VERSION ""

NS_ :

BS_:

BU_: USCU LSU LCU VCU ACU
VAL_TABLE_ Agv_St 2 "ON" 1 "STOP" 0 "Inivd" ;

BO_ 3221225472 VECTOR__INDEPENDENT_SIG_MSG: 0 Vector__XXX
 SG_ VCU1_RemoteValid : 0|1@1+ (1,0) [0|1] "" Vector__XXX

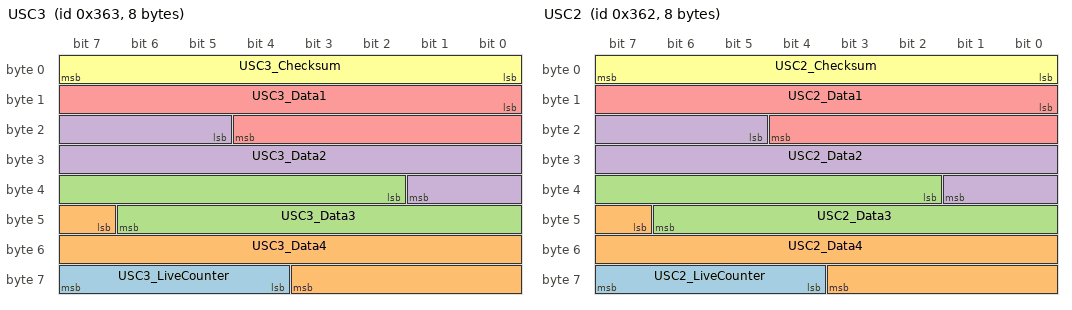
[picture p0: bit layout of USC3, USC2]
BO_ 867 USC3: 8 USCU
 SG_ USC3_LiveCounter : 60|4@1+ (1,0) [0|15] "" Vector__XXX
 SG_ USC3_Data4 : 47|13@1+ (1,0) [0|5000] "mm" Vector__XXX
 SG_ USC3_Data3 : 34|13@1+ (1,0) [0|5000] "mm" Vector__XXX
 SG_ USC3_Data2 : 21|13@1+ (1,0) [0|5000] "mm" Vector__XXX
 SG_ USC3_Data1 : 8|13@1+ (1,0) [0|5000] "mm" Vector__XXX
 SG_ USC3_Checksum : 0|8@1+ (1,0) [0|255] "" Vector__XXX

BO_ 866 USC2: 8 USCU
 SG_ USC2_LiveCounter : 60|4@1+ (1,0) [0|15] "" Vector__XXX
 SG_ USC2_Data4 : 47|13@1+ (1,0) [0|5000] "" Vector__XXX
 SG_ USC2_Data3 : 34|13@1+ (1,0) [0|5000] "mm" Vector__XXX
 SG_ USC2_Data2 : 21|13@1+ (1,0) [0|5000] "mm" Vector__XXX
 SG_ USC2_Data1 : 8|13@1+ (1,0) [0|5000] "mm" Vector__XXX
 SG_ USC2_Checksum : 0|8@1+ (1,0) [0|255] "" Vector__XXX

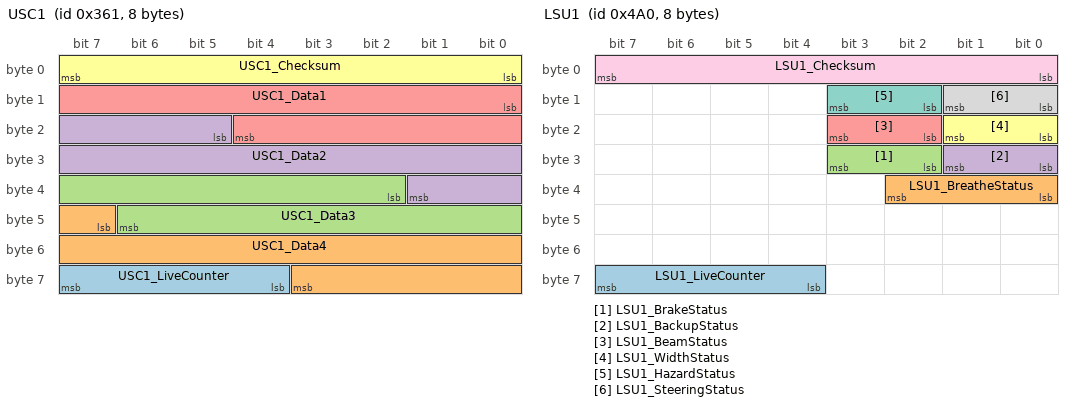
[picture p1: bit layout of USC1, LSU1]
BO_ 865 USC1: 8 USCU
 SG_ USC1_LiveCounter : 60|4@1+ (1,0) [0|15] "" Vector__XXX
 SG_ USC1_Data4 : 47|13@1+ (1,0) [0|5000] "mm" Vector__XXX
 SG_ USC1_Data3 : 34|13@1+ (1,0) [0|5000] "mm" Vector__XXX
 SG_ USC1_Data2 : 21|13@1+ (1,0) [0|5000] "mm" Vector__XXX
 SG_ USC1_Data1 : 8|13@1+ (1,0) [0|5000] "mm" Vector__XXX
 SG_ USC1_Checksum : 0|8@1+ (1,0) [0|255] "" Vector__XXX

BO_ 1184 LSU1: 8 LSU
 SG_ LSU1_LiveCounter : 60|4@1+ (1,0) [0|15] "count" Vector__XXX
 SG_ LSU1_BreatheStatus : 32|3@1+ (1,0) [0|1] "" Vector__XXX
 SG_ LSU1_BrakeStatus : 26|2@1+ (1,0) [0|3] "" Vector__XXX
 SG_ LSU1_BackupStatus : 24|2@1+ (1,0) [0|3] "" Vector__XXX
 SG_ LSU1_BeamStatus : 18|2@1+ (1,0) [0|1] "" Vector__XXX
 SG_ LSU1_WidthStatus : 16|2@1+ (1,0) [0|3] "" Vector__XXX
 SG_ LSU1_HazardStatus : 10|2@1+ (1,0) [0|3] "" Vector__XXX
 SG_ LSU1_SteeringStatus : 8|2@1+ (1,0) [0|1] "" Vector__XXX
 SG_ LSU1_Checksum : 0|8@1+ (1,0) [0|255] "check" Vector__XXX

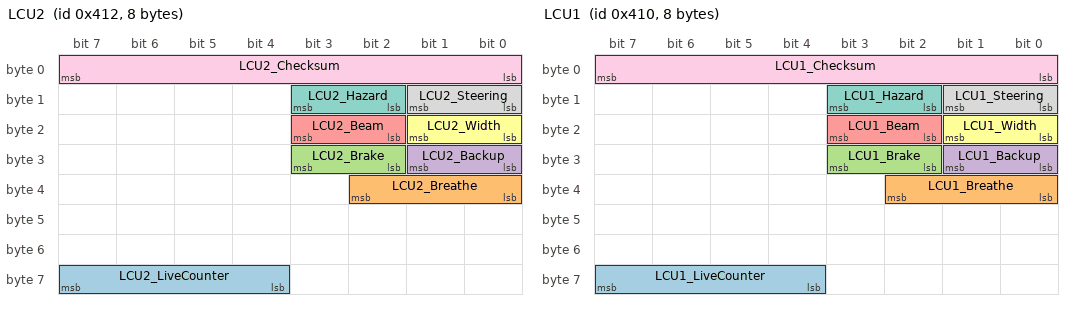
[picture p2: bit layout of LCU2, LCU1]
BO_ 1042 LCU2: 8 LCU
 SG_ LCU2_LiveCounter : 60|4@1+ (1,0) [0|15] "count" Vector__XXX
 SG_ LCU2_Breathe : 32|3@1+ (1,0) [0|3] "" Vector__XXX
 SG_ LCU2_Brake : 26|2@1+ (1,0) [0|3] "" Vector__XXX
 SG_ LCU2_Backup : 24|2@1+ (1,0) [0|3] "" Vector__XXX
 SG_ LCU2_Beam : 18|2@1+ (1,0) [0|3] "" Vector__XXX
 SG_ LCU2_Width : 16|2@1+ (1,0) [0|3] "" Vector__XXX
 SG_ LCU2_Hazard : 10|2@1+ (1,0) [0|3] "" Vector__XXX
 SG_ LCU2_Steering : 8|2@1+ (1,0) [0|3] "" Vector__XXX
 SG_ LCU2_Checksum : 0|8@1+ (1,0) [0|255] "check" Vector__XXX

BO_ 1040 LCU1: 8 LCU
 SG_ LCU1_LiveCounter : 60|4@1+ (1,0) [0|15] "count" Vector__XXX
 SG_ LCU1_Breathe : 32|3@1+ (1,0) [0|3] "" Vector__XXX
 SG_ LCU1_Brake : 26|2@1+ (1,0) [0|3] "" Vector__XXX
 SG_ LCU1_Backup : 24|2@1+ (1,0) [0|3] "" Vector__XXX
 SG_ LCU1_Beam : 18|2@1+ (1,0) [0|3] "" Vector__XXX
 SG_ LCU1_Width : 16|2@1+ (1,0) [0|3] "" Vector__XXX
 SG_ LCU1_Hazard : 10|2@1+ (1,0) [0|3] "" Vector__XXX
 SG_ LCU1_Steering : 8|2@1+ (1,0) [0|3] "" Vector__XXX
 SG_ LCU1_Checksum : 0|8@1+ (1,0) [0|255] "check" Vector__XXX

BO_ 801 Agv: 8 Vector__XXX
 SG_ Agv_Message_St : 0|2@1+ (1,0) [0|0] "" Vector__XXX

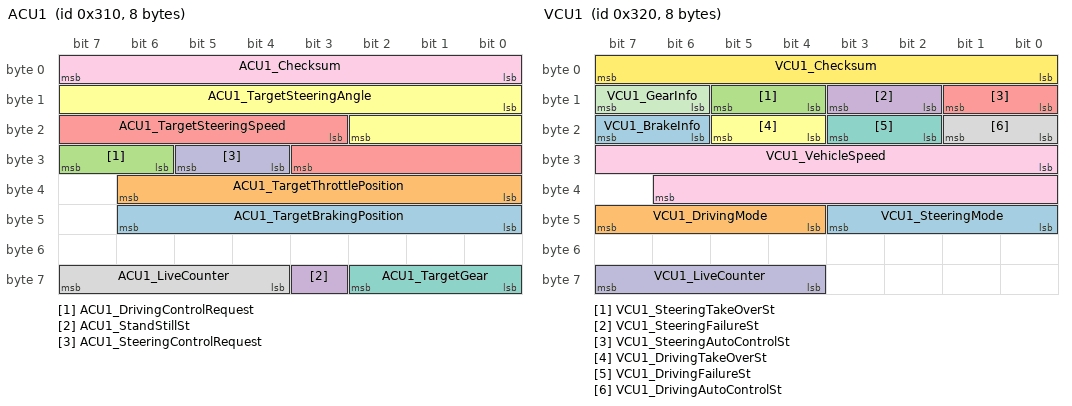
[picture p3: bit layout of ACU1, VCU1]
BO_ 784 ACU1: 8 ACU
 SG_ ACU1_TargetBrakingPosition : 40|7@1+ (1,0) [0|100] "%" Vector__XXX
 SG_ ACU1_TargetThrottlePosition : 32|7@1+ (1,0) [0|100] "%" Vector__XXX
 SG_ ACU1_DrivingControlRequest : 30|2@1+ (1,0) [0|3] "" Vector__XXX
 SG_ ACU1_StandStillSt : 59|1@1+ (1,0) [0|1] "" Vector__XXX
 SG_ ACU1_TargetSteeringSpeed : 19|9@1+ (1,0) [0|500] "deg/s" Vector__XXX
 SG_ ACU1_TargetSteeringAngle : 8|11@1+ (1,-600) [-600|600] "deg" Vector__XXX
 SG_ ACU1_TargetGear : 56|3@1+ (1,0) [0|7] "" Vector__XXX
 SG_ ACU1_LiveCounter : 60|4@1+ (1,0) [0|15] "" Vector__XXX
 SG_ ACU1_Checksum : 0|8@1+ (1,0) [0|255] "" Vector__XXX
 SG_ ACU1_SteeringControlRequest : 28|2@1+ (1,0) [0|3] "" Vector__XXX

BO_ 800 VCU1: 8 VCU
 SG_ VCU1_SteeringMode : 40|4@1+ (1,0) [0|15] "" Vector__XXX
 SG_ VCU1_DrivingMode : 44|4@1+ (1,0) [0|15] "" Vector__XXX
 SG_ VCU1_SteeringTakeOverSt : 12|2@1+ (1,0) [0|3] "" Vector__XXX
 SG_ VCU1_SteeringFailureSt : 10|2@1+ (1,0) [0|3] "" Vector__XXX
 SG_ VCU1_SteeringAutoControlSt : 8|2@1+ (1,0) [0|3] "" Vector__XXX
 SG_ VCU1_DrivingTakeOverSt : 20|2@1+ (1,0) [0|3] "" Vector__XXX
 SG_ VCU1_DrivingFailureSt : 18|2@1+ (1,0) [0|3] "" Vector__XXX
 SG_ VCU1_DrivingAutoControlSt : 16|2@1+ (1,0) [0|3] "" Vector__XXX
 SG_ VCU1_VehicleSpeed : 24|15@1+ (1,0) [0|60] "km/h" Vector__XXX
 SG_ VCU1_LiveCounter : 60|4@1+ (1,0) [0|15] "" Vector__XXX
 SG_ VCU1_GearInfo : 14|2@1+ (1,0) [0|3] "" Vector__XXX
 SG_ VCU1_Checksum : 0|8@1+ (1,0) [0|255] "" Vector__XXX
 SG_ VCU1_BrakeInfo : 22|2@1+ (1,0) [0|3] "" Vector__XXX

CM_ BO_ 3221225472 "This is a message for not used signals, created by Vector CANdb++ DBC OLE DB Provider.";
CM_ SG_ 3221225472 VCU1_RemoteValid "Ò£¿ØÆ÷ÓÐÐ§×´Ì¬";
BA_DEF_ BO_  "GenMsgType" ENUM  "N","T","R";
BA_DEF_  "VersionYear" INT 0 2099;
BA_DEF_  "VersionMonth" INT 0 12;
BA_DEF_  "VersionDay" INT 0 31;
BA_DEF_  "Baudrate" INT 0 1000000;
BA_DEF_ BO_  "GenMsgCycleTime" INT 0 10000;
BA_DEF_  "DBName" STRING ;
BA_DEF_  "BusType" STRING ;
BA_DEF_DEF_  "GenMsgType" "N";
BA_DEF_DEF_  "VersionYear" 2020;
BA_DEF_DEF_  "VersionMonth" 1;
BA_DEF_DEF_  "VersionDay" 1;
BA_DEF_DEF_  "Baudrate" 500000;
BA_DEF_DEF_  "GenMsgCycleTime" 10;
BA_DEF_DEF_  "DBName" "VENUS";
BA_DEF_DEF_  "BusType" "CAN";
BA_ "DBName" "KFC";
BA_ "GenMsgType" BO_ 784 2;
BA_ "GenMsgCycleTime" BO_ 784 20;
BA_ "GenMsgType" BO_ 800 1;
VAL_ 3221225472 VCU1_RemoteValid 3 "Reserved" 2 "Active" 1 "Temporary" 0 "Inactive" ;
VAL_ 1184 LSU1_BreatheStatus 7 "Invalid" 6 "Always On" 5 "Interval 4s" 4 "Interval 3s" 3 "Interval 2s" 2 "Interval 1s" 1 "Interval 500ms" 0 "Off" ;
VAL_ 1184 LSU1_BrakeStatus 3 "Invalid" 2 "Reserved" 1 "Off" 0 "Off" ;
VAL_ 1184 LSU1_BackupStatus 3 "Invalid" 2 "Reserved" 1 "On" 0 "Off" ;
VAL_ 1184 LSU1_BeamStatus 3 "Invalid" 2 "Reserved" 1 "On" 0 "Off" ;
VAL_ 1184 LSU1_WidthStatus 3 "Invalid" 2 "Reserved" 1 "On" 0 "Off" ;
VAL_ 1184 LSU1_HazardStatus 3 "Invalid" 2 "Reserved" 1 "On" 0 "Off" ;
VAL_ 1184 LSU1_SteeringStatus 3 "Invalid" 2 "Right" 1 "Left" 0 "Off" ;
VAL_ 1042 LCU2_Breathe 7 "Always On" 6 "Interval 4s" 5 "Interval 3s" 4 "Interval 2s" 3 "Interval 1s" 2 "Interval 500ms" 1 "Off" 0 "No Request" ;
VAL_ 1042 LCU2_Brake 3 "Reserved" 2 "On" 1 "Off" 0 "No Request" ;
VAL_ 1042 LCU2_Backup 3 "Reserved" 2 "On" 1 "Off" 0 "NoRequest" ;
VAL_ 1042 LCU2_Beam 3 "High" 2 "Low" 1 "Off" 0 "No Request" ;
VAL_ 1042 LCU2_Width 3 "Reserved" 2 "On" 1 "Off" 0 "No Request" ;
VAL_ 1042 LCU2_Hazard 3 "Reserved" 2 "On" 1 "Off" 0 "No Request" ;
VAL_ 1042 LCU2_Steering 3 "Right" 2 "Left" 1 "Off" 0 "No Request" ;
VAL_ 1040 LCU1_Breathe 7 "Always On" 6 "Interval 4s" 5 "Interval 3s" 4 "Interval 2s" 3 "Interval 1s" 2 "Interval 500ms" 1 "Off" 0 "No Request" ;
VAL_ 1040 LCU1_Brake 3 "Reserved" 2 "On" 1 "Off" 0 "No Request" ;
VAL_ 1040 LCU1_Backup 3 "Reserved" 2 "On" 1 "Off" 0 "NoRequest" ;
VAL_ 1040 LCU1_Beam 3 "High" 2 "Low" 1 "Off" 0 "No Request" ;
VAL_ 1040 LCU1_Width 3 "Reserved" 2 "On" 1 "Off" 0 "No Request" ;
VAL_ 1040 LCU1_Hazard 3 "Reserved" 2 "On" 1 "Off" 0 "No Request" ;
VAL_ 1040 LCU1_Steering 3 "Right" 2 "Left" 1 "Off" 0 "No Request" ;
VAL_ 801 Agv_Message_St 2 "ON" 1 "STOP" 0 "Inivd" ;
VAL_ 784 ACU1_DrivingControlRequest 3 "Reserved" 2 "Reserved" 1 "Request" 0 "No Requet" ;
VAL_ 784 ACU1_StandStillSt 1 "Active" 0 "Inactive" ;
VAL_ 784 ACU1_TargetGear 7 "Reserved" 6 "Reserved" 5 "Reserved" 4 "R" 3 "N" 2 "D" 1 "P" 0 "No Request" ;
VAL_ 784 ACU1_SteeringControlRequest 3 "Reserved" 2 "Reserved" 1 "Request" 0 "No Requet" ;
VAL_ 800 VCU1_SteeringTakeOverSt 3 "Reserved" 2 "Active" 1 "Temporary" 0 "Inactive" ;
VAL_ 800 VCU1_SteeringFailureSt 3 "Reserved" 2 "SAS Fail" 1 "EPS Fail" 0 "No Fail" ;
VAL_ 800 VCU1_SteeringAutoControlSt 3 "Reserved" 2 "Reserved" 1 "Active" 0 "Inactive" ;
VAL_ 800 VCU1_DrivingTakeOverSt 3 "Reserved" 2 "Take Over" 1 "Temporary" 0 "Inactive" ;
VAL_ 800 VCU1_DrivingFailureSt 3 "Reserved" 2 "Motor Fail" 1 "HCU Fail" 0 "No Fail" ;
VAL_ 800 VCU1_DrivingAutoControlSt 3 "Reserved" 2 "Reserved" 1 "Active" 0 "Inactive" ;
VAL_ 800 VCU1_GearInfo 3 "D" 2 "N" 1 "R" 0 "P" ;
VAL_ 800 VCU1_BrakeInfo 3 "Reserved" 2 "Reserved" 1 "Active" 0 "Inactive" ;
